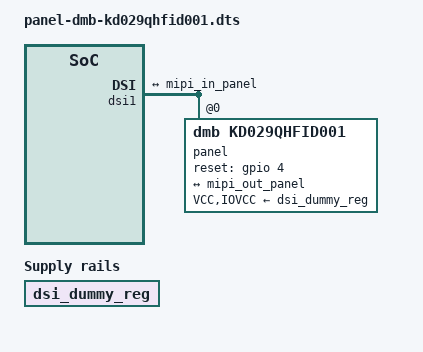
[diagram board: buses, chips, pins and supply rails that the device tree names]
/dts-v1/;
/plugin/;

/{
    dsi_dummy_reg: dsi_dummy_reg {
		compatible = "regulator-fixed";
		regulator-name = "dsi_dummy_reg";
		status = "okay";
	};

    fragment@0 {
        target = <&dsi1>;
        __overlay__ {
            status = "okay";
            #address-cells = <1>;
            #size-cells = <0>;

            port {
                mipi_out_panel: endpoint {
                    remote-endpoint = <&mipi_in_panel>;
                };
            };

            panel@0 {
                compatible = "dmb,kd029qhfid001";
                reg = <0>;
                reset-gpios = <&gpio 4 0>;
                VCC-supply = <&dsi_dummy_reg>;
                IOVCC-supply = <&dsi_dummy_reg>;

                port {
                    mipi_in_panel: endpoint {
                        remote-endpoint = <&mipi_out_panel>;
                    };
                };
            };
        };
    };
};
